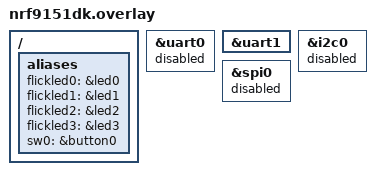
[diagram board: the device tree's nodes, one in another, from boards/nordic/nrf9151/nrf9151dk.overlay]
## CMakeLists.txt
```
# SPDX-License-Identifier: Apache-2.0
cmake_minimum_required(VERSION 3.20.0)

set(CMAKE_EXPORT_COMPILE_COMMANDS ON)
set(CMAKE_CXX_STANDARD 17)
set(CMAKE_CXX_STANDARD_REQUIRED ON)

# Board-named overlays are discovered by Zephyr; QEMU gets no Nordic overlay.
# DTC_OVERLAY_FILE can still be provided explicitly by the caller.

# Installation paths belong to each machine, not to this repository.
# Accept -DZEPHYR_BASE=... or ZEPHYR_BASE from the environment; registered
# Zephyr packages are also supported. Quote paths on all host platforms.
# Let Zephyr select the cross compiler using BOARD and its toolchain settings
# (e.g. ZEPHYR_TOOLCHAIN_VARIANT and ZEPHYR_SDK_INSTALL_DIR).
find_package(Zephyr REQUIRED HINTS "${ZEPHYR_BASE}" "$ENV{ZEPHYR_BASE}")
project(peripheral LANGUAGES C CXX ASM)

# Keep the application entry point here; modules register their own sources.
target_sources(app PRIVATE "${CMAKE_CURRENT_SOURCE_DIR}/src/main.cpp")
add_subdirectory(include)
add_subdirectory(src)
```

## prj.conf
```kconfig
CONFIG_UART_CONSOLE=y



CONFIG_LOG=y
#interrupts  
#CONFIG_IRQ=y 
CONFIG_GPIO=y
# CONFIG_SHARED_INTERRUPTS=n

#enabling non secure GPIOTE driver for nrf91
# Security mode is selected by the nRF9151 board target.



CONFIG_CPP=y
CONFIG_STD_CPP17=y

CONFIG_CONSOLE=y
CONFIG_UART_CONSOLE=n
CONFIG_USE_SEGGER_RTT=y
CONFIG_RTT_CONSOLE=y

# GPIO register backend owns GPIOTE; keep the GPIO driver from claiming its IRQ.
# Nordic GPIO interrupt ownership is configured in boards/*.conf.


#debug 
CONFIG_LOG=y
CONFIG_LOG_DEFAULT_LEVEL=4

# 
# CONFIG_CPP=y
# CONFIG_STD_CPP17=y
CONFIG_GPIO_NRFX_INTERRUPT=n
```

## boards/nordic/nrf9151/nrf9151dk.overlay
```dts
/*
 * Reuse the nRF9151 DK board nodes instead of creating duplicate devices.
 * The right-hand labels come from nrf9151dk_nrf9151_common.dtsi.
 * These mappings already match the board defaults; they are explicit here
 * so the application aliases can be changed without redefining pin wiring.
 * gpio_interrupt.cpp currently uses raw pin constants; these aliases are an
 * optional alternative shown in comments there, not its active pin source.
 */

/ {
	aliases {
		flickled0 = &led0;       /* Board LED 1: P0.00 */
		flickled1 = &led1;       /* Board LED 2: P0.01 */
		flickled2 = &led2;       /* Board LED 3: P0.04 */
		flickled3 = &led3;       /* Board LED 4: P0.05 */
		sw0 = &button0;    /* Board button 1: P0.08 */
	};
};


&uart0 {
status = "disabled";
};
&uart1 {

status = "okay";
};

  &i2c0{
	status = "disabled";
  };

&spi0{

	status = "disabled";
};
```

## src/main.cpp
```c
#include <zephyr/kernel.h>
#include "gpio/gpio_interrupt.hpp"
#include "gpio/i2c.hpp"

extern "C" int main(void)
{


    while (true) {
        k_msleep(1000);
    }

    return 0;
}
```
